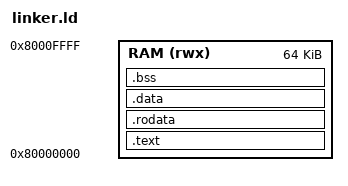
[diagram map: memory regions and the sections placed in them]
OUTPUT_ARCH(riscv)
ENTRY(_start)

MEMORY {
    RAM (rwx) : ORIGIN = 0x80000000, LENGTH = 64K
}

SECTIONS {
    .text : {
        *(.text.start)
        *(.text .text.*)
    } > RAM

    .rodata : {
        *(.rodata .rodata.*)
        *(.srodata .srodata.*)
    } > RAM

    .data : {
        *(.data .data.*)
        *(.sdata .sdata.*)
    } > RAM

    .bss : {
        *(.bss .bss.*)
        *(.sbss .sbss.*)
    } > RAM
}
